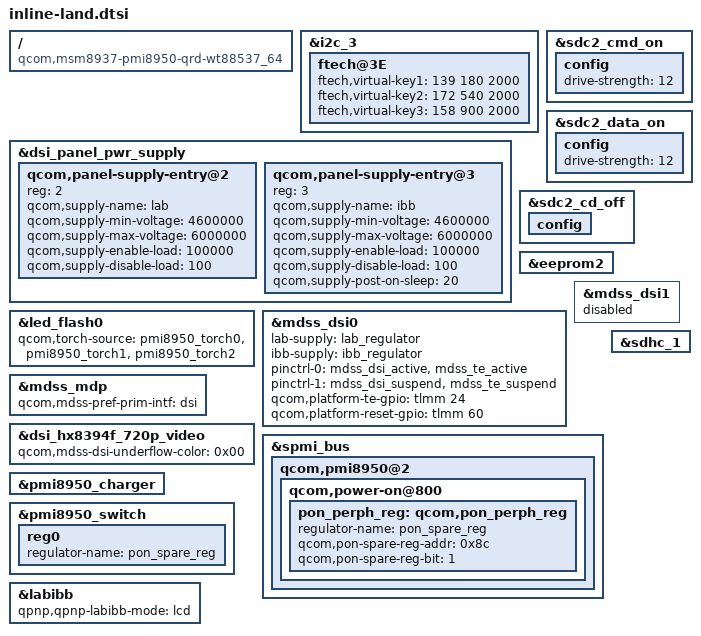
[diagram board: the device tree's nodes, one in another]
#include "inline-common.dtsi"

/ {
	/* Changed: qcom,msm8937-pmi8950-qrd-sku1 => qcom,msm8937-pmi8950-qrd-wt88537_64 */
	compatible = "qcom,msm8937-pmi8950-qrd-wt88537_64",
		   "qcom,msm8937-qrd", "qcom,msm8937", "qcom,qrd";
};

&i2c_3 {
	ftech@3E {
		/delete-property/ ftech,button-map;
		/delete-property/ ftech,button-x-coords;
		/delete-property/ ftech,button-y-coord;
		ftech,virtual-key1 = <139 180 2000>;/*menu*/
		ftech,virtual-key2 = <172 540 2000>;/*home*/
		ftech,virtual-key3 = <158 900 2000>;/*back*/
	};
};

&dsi_panel_pwr_supply {
	qcom,panel-supply-entry@2 {
		reg = <2>;
		qcom,supply-name = "lab";
		qcom,supply-min-voltage = <4600000>;
		qcom,supply-max-voltage = <6000000>;
		qcom,supply-enable-load = <100000>;
		qcom,supply-disable-load = <100>;
	};

	qcom,panel-supply-entry@3 {
		reg = <3>;
		qcom,supply-name = "ibb";
		qcom,supply-min-voltage = <4600000>;
		qcom,supply-max-voltage = <6000000>;
		qcom,supply-enable-load = <100000>;
		qcom,supply-disable-load = <100>;
		qcom,supply-post-on-sleep = <20>;
	};
};

&sdc2_cmd_on {
	config {
		drive-strength = <12>;
	};
};

&sdc2_data_on {
	config {
		drive-strength = <12>;
	};
};

&sdc2_cd_off {
	config {
		/delete-property/ bias-disable;
	};
};

&led_flash0 {
	/* Added: &pmi8950_torch2 */
	qcom,torch-source = <&pmi8950_torch0 &pmi8950_torch1 &pmi8950_torch2>;
};

&eeprom2 {
	/delete-property/ qcom,clock-rates;
};

&mdss_dsi0 {
	lab-supply = <&lab_regulator>;
	ibb-supply = <&ibb_regulator>;
	pinctrl-names = "mdss_default", "mdss_sleep";
	pinctrl-0 = <&mdss_dsi_active &mdss_te_active>;
	pinctrl-1 = <&mdss_dsi_suspend &mdss_te_suspend>;
	qcom,platform-te-gpio = <&tlmm 24 0>;
	qcom,platform-reset-gpio = <&tlmm 60 0>;
};

&mdss_dsi1 {
	status = "disabled";
};

&mdss_mdp {
	qcom,mdss-pref-prim-intf = "dsi";
};

&dsi_hx8394f_720p_video {
	qcom,mdss-dsi-underflow-color = <0x00>;
};

/* TODO: Checkout from land-m-oss:
	qcom,mdss_dsi_hx8394f_boe_720p_video
	qcom,mdss_dsi_ili9881c_tianma_720p_video
	qcom,mdss_dsi_nt35521s_ebbg_720p_video
*/

&spmi_bus {
	qcom,pmi8950@2 {
		qcom,power-on@800 {
			pon_perph_reg: qcom,pon_perph_reg {
				regulator-name = "pon_spare_reg";
				qcom,pon-spare-reg-addr = <0x8c>;
				qcom,pon-spare-reg-bit = <1>;
			};
		};
	};
};

&pmi8950_charger {
	/delete-property/ qcom,parallel-allowed-lowering-ma;
	/delete-property/ qcom,parallel-usb-9v-min-current-ma;
	/delete-property/ qcom,parallel-usb-min-current-ma;

	/delete-node/ qcom,qpnp-smbcharger;
};

&pmi8950_switch {
	reg0 {
		regulator-name = "pon_spare_reg";
	};
};

&labibb {
	status = "ok";
	qpnp,qpnp-labibb-mode = "lcd";
};

&sdhc_1 {
	/delete-property/ qcom,vdd-always-on;
};
